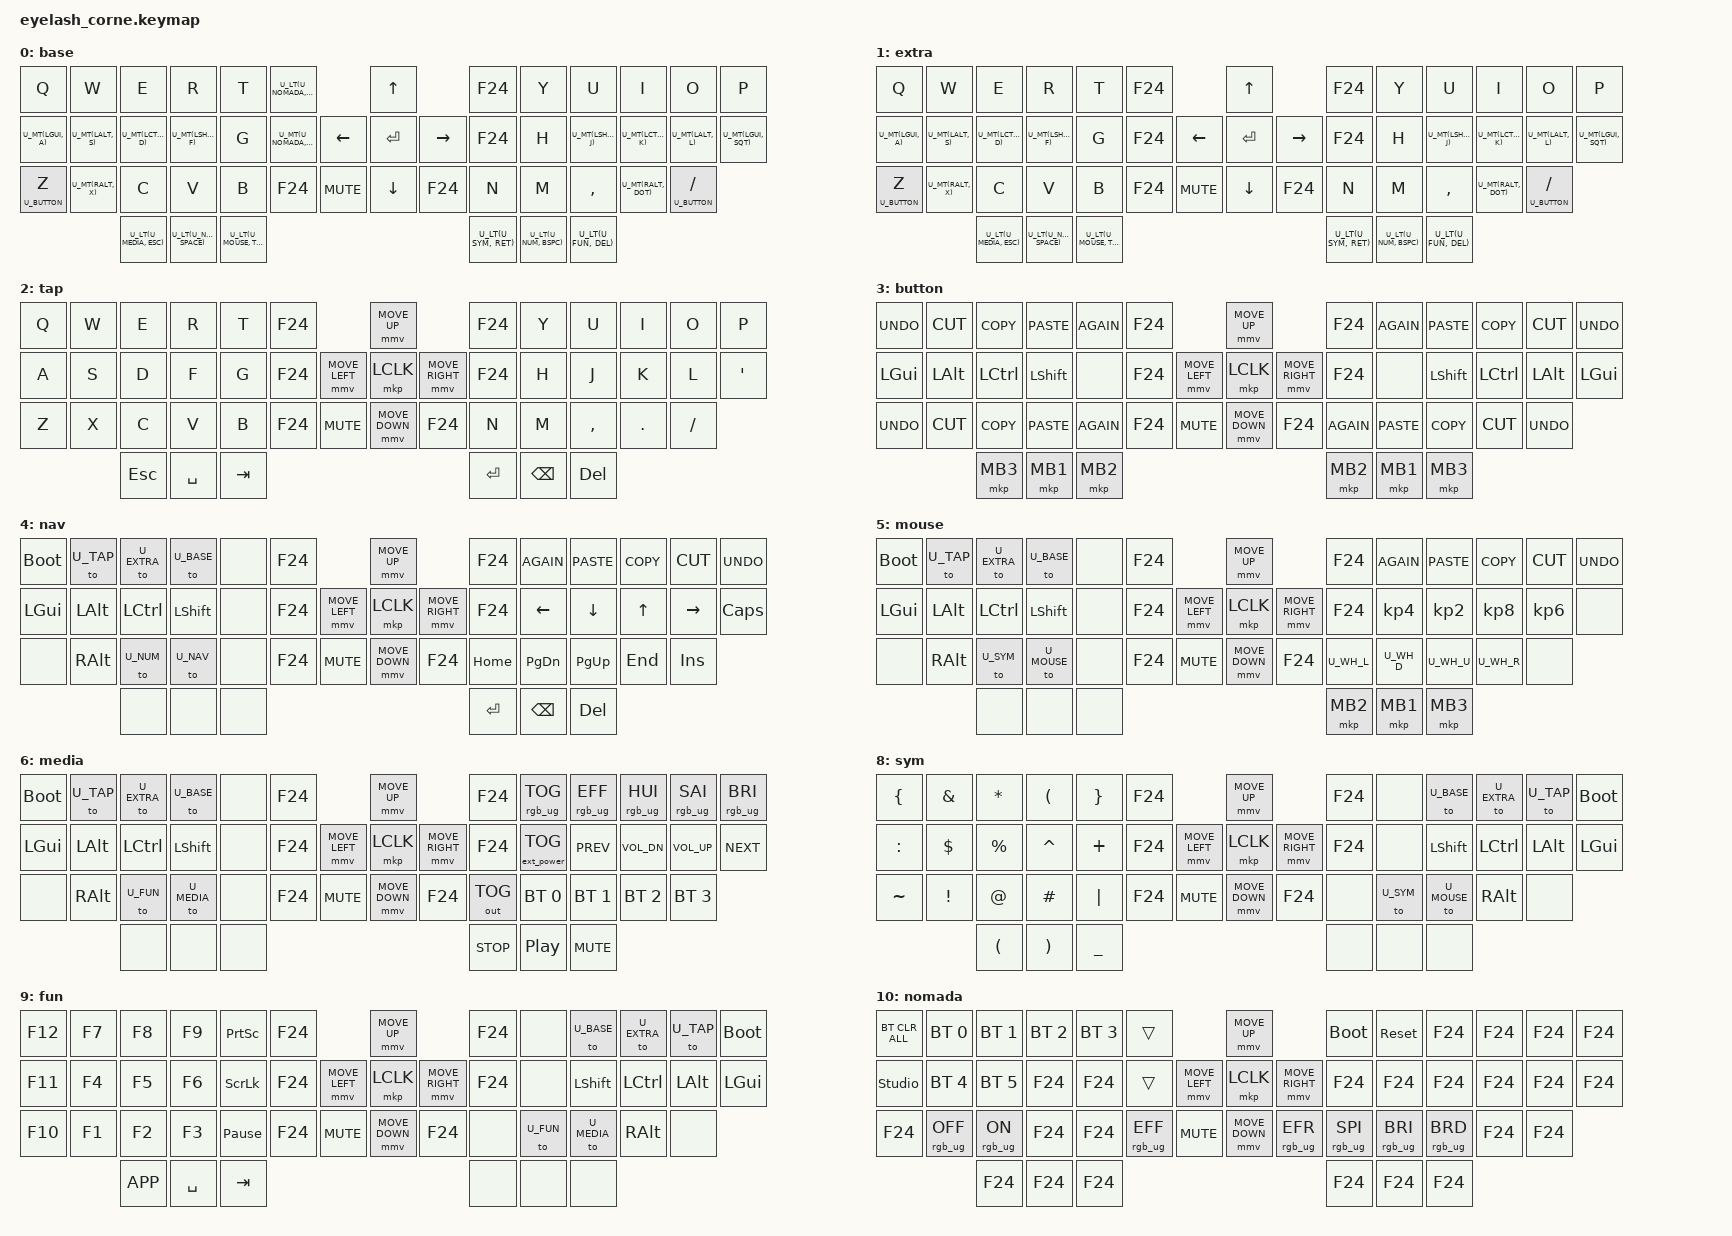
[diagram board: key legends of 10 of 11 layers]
#include <behaviors.dtsi>
#include <dt-bindings/zmk/bt.h>
#include <dt-bindings/zmk/keys.h>
#include <dt-bindings/zmk/mouse.h>
#include <dt-bindings/zmk/outputs.h>
#include <dt-bindings/zmk/rgb.h>
#include <dt-bindings/zmk/ext_power.h>

#include <input/processors.dtsi>

/*

   &mmv_input_listener {
       input-processors = <&zip_xy_scaler 2 1>;
   };

   &msc_input_listener {
       input-processors = <&zip_xy_scaler 2 1>;
   };

 */

#define ZMK_MOUSE_DEFAULT_MOVE_VAL 1200  // 600
#define ZMK_MOUSE_DEFAULT_SCRL_VAL 20    // 10


#define U_RDO &kp K_AGAIN
#define U_PST &kp K_PASTE
#define U_CPY &kp K_COPY
#define U_CUT &kp K_CUT
#define U_UND &kp K_UNDO


#define U_NP &none // key is not present
#define U_NA &none // present but not available for use
#define U_NU &none // available but not used


#define U_MT(MOD, TAP) &u_mt MOD TAP
#define U_LT(LAYER, TAP) &u_lt LAYER TAP


#define U_BASE   0
#define U_EXTRA  1
#define U_TAP    2
#define U_BUTTON 3
#define U_NAV    4
#define U_MOUSE  5
#define U_MEDIA  6
#define U_NUM    7
#define U_SYM    8
#define U_FUN    9
#define U_NOMADA 10

#define U_TAPPING_TERM 200
 
#define U_MS_D &kp KP_N2
#define U_MS_L &kp KP_N4
#define U_MS_R &kp KP_N6
#define U_MS_U &kp KP_N8
#define U_WH_D U_NU
#define U_WH_L U_NU
#define U_WH_R U_NU
#define U_WH_U U_NU


#define U_RGB_TOG &rgb_ug RGB_TOG
#define U_RGB_EFF &rgb_ug RGB_EFF
#define U_RGB_HUI &rgb_ug RGB_HUI
#define U_RGB_SAI &rgb_ug RGB_SAI
#define U_RGB_BRI &rgb_ug RGB_BRI
#define U_EP_TOG &ext_power EP_TOG

#define U_BTN1 &mkp MB1
#define U_BTN2 &mkp MB2
#define U_BTN3 &mkp MB3

// #define MIRYOKU_DOUBLE_TAP_GUARD(NAME, BINDING) \
// / { \
//   behaviors { \
//     NAME: NAME { \
//       compatible = "zmk,behavior-tap-dance"; \
//       #binding-cells = <0>; \
//       tapping-term-ms = <U_TAPPING_TERM>; \
//       bindings = <&none>, <BINDING>; \
//     }; \
//   }; \
// };

// #define MIRYOKU_X(LAYER, STRING) \
// MIRYOKU_DOUBLE_TAP_GUARD(u_to_U_##LAYER, &to U_##LAYER)
// MIRYOKU_LAYER_LIST
// #undef MIRYOKU_X


// #define MIRYOKU_SHIFT_FUNCTION(NAME, BINDING, SHIFT_BINDING) \
// / { \
//   behaviors { \
//     NAME: NAME { \
//       compatible = "zmk,behavior-mod-morph"; \
//       #binding-cells = <0>; \
//       bindings = <BINDING>, <SHIFT_BINDING>; \
//       mods = <(MOD_LSFT|MOD_RSFT)>; \
//     }; \
//   }; \
// };

// #define MIRYOKU_SHIFT_MACRO(NAME, BINDING, SHIFT_BINDING) \
// U_MACRO(u_macro_ ## NAME, wait-ms = <0>; bindings = <SHIFT_BINDING>;) \
// MIRYOKU_SHIFT_FUNCTION(NAME, BINDING, &u_macro_ ## NAME)

// MIRYOKU_SHIFT_MACRO(u_bt_sel_0, &bt BT_SEL 0, &bt BT_SEL 0 &bt BT_CLR)
// MIRYOKU_SHIFT_MACRO(u_bt_sel_1, &bt BT_SEL 1, &bt BT_SEL 1 &bt BT_CLR)
// MIRYOKU_SHIFT_MACRO(u_bt_sel_2, &bt BT_SEL 2, &bt BT_SEL 2 &bt BT_CLR)
// MIRYOKU_SHIFT_MACRO(u_bt_sel_3, &bt BT_SEL 3, &bt BT_SEL 3 &bt BT_CLR)
// MIRYOKU_SHIFT_MACRO(u_bt_sel_4, &bt BT_SEL 4, &bt BT_SEL 4 &bt BT_CLR)
// MIRYOKU_SHIFT_FUNCTION(u_caps_word, &caps_word, &kp CAPS)

// MIRYOKU_SHIFT_FUNCTION(u_out_tog, &out OUT_TOG, &out OUT_USB)

/ {
    behaviors {
        td0: td0 {
            compatible = "zmk,behavior-tap-dance";
            display-name = "Shift/Caps Lock Tap Dance";
            #binding-cells = <0>;
            bindings = <&kp LEFT_SHIFT>, <&kp CAPS>;
        };

        u_mt: u_mt {
            compatible = "zmk,behavior-hold-tap";
            #binding-cells = <2>;
            tapping-term-ms = <U_TAPPING_TERM>;
            flavor = "tap-preferred";
            bindings = <&kp>, <&kp>;
        };

        u_lt: u_lt {
            compatible = "zmk,behavior-hold-tap";
            #binding-cells = <2>;
            tapping-term-ms = <U_TAPPING_TERM>;
            flavor = "tap-preferred";
            bindings = <&mo>, <&kp>;
        };

        gresc: grave_escape {
            compatible = "zmk,behavior-mod-morph";
            #binding-cells = <0>;
            bindings = <&kp ESC>, <&kp GRAVE>;
            mods = <(MOD_LGUI|MOD_LSFT|MOD_RGUI|MOD_RSFT)>;
        };

    };

    rgb_encoder: rgb_encoder {
        compatible = "zmk,behavior-sensor-rotate";
        #sensor-binding-cells = <0>;
        bindings = <&rgb_ug RGB_BRI>, <&rgb_ug RGB_BRD>;
    };

    scroll_encoder: scroll_encoder {
        compatible = "zmk,behavior-sensor-rotate";
        #sensor-binding-cells = <0>;
        bindings = <&msc SCRL_DOWN>, <&msc SCRL_UP>;
        tap-ms = <30>;
    };

    keymap {
        compatible = "zmk,keymap";

    layer_base {
            display-name = "base";
            bindings = <
&kp Q           &kp W          &kp E               &kp R               &kp T  U_LT(U_NOMADA, A)                                 &kp UP                &kp F24           &kp Y              &kp U            &kp I           &kp O            &kp P
U_MT(LGUI, A)   U_MT(LALT, S)  U_MT(LCTRL, D)      U_MT(LSHFT, F)      &kp G  U_MT(U_NOMADA, A)                     &kp LEFT  &kp ENTER  &kp RIGHT  &kp F24           &kp H              U_MT(LSHFT, J)   U_MT(LCTRL, K)  U_MT(LALT, L)    U_MT(LGUI, SQT)
&lt U_BUTTON Z  U_MT(RALT, X)  &kp C               &kp V               &kp B  &kp F24     &kp C_MUTE                &kp DOWN              &kp F24           &kp N              &kp M            &kp COMMA       U_MT(RALT, DOT)  &lt U_BUTTON SLASH
                               U_LT(U_MEDIA, ESC)  U_LT(U_NAV, SPACE)  U_LT(U_MOUSE, TAB)                                                  U_LT(U_SYM, RET)  U_LT(U_NUM, BSPC)  U_LT(U_FUN, DEL)
            >;
            sensor-bindings = <&scroll_encoder>;
        };

        layer_extra {
            display-name = "extra";
            bindings = <
&kp Q           &kp W          &kp E               &kp R               &kp T  &kp F24                               &kp UP                &kp F24           &kp Y              &kp U            &kp I           &kp O            &kp P
U_MT(LGUI, A)   U_MT(LALT, S)  U_MT(LCTRL, D)      U_MT(LSHFT, F)      &kp G  &kp F24                     &kp LEFT  &kp ENTER  &kp RIGHT  &kp F24           &kp H              U_MT(LSHFT, J)   U_MT(LCTRL, K)  U_MT(LALT, L)    U_MT(LGUI, SQT)
&lt U_BUTTON Z  U_MT(RALT, X)  &kp C               &kp V               &kp B  &kp F24     &kp C_MUTE                &kp DOWN              &kp F24           &kp N              &kp M            &kp COMMA       U_MT(RALT, DOT)  &lt U_BUTTON SLASH
                               U_LT(U_MEDIA, ESC)  U_LT(U_NAV, SPACE)  U_LT(U_MOUSE, TAB)                                                  U_LT(U_SYM, RET)  U_LT(U_NUM, BSPC)  U_LT(U_FUN, DEL)
            >;
            sensor-bindings = <&scroll_encoder>;
        };

        layer_tap {
            display-name = "tap";
            bindings = <
&kp Q           &kp W  &kp E    &kp R      &kp T    &kp F24                              &mmv MOVE_UP                     &kp F24  &kp Y     &kp U    &kp I      &kp O    &kp P
&kp A           &kp S  &kp D    &kp F      &kp G    &kp F24              &mmv MOVE_LEFT  &mkp LCLK       &mmv MOVE_RIGHT  &kp F24  &kp H     &kp J    &kp K      &kp L    &kp SQT
&kp Z           &kp X  &kp C    &kp V      &kp B    &kp F24  &kp C_MUTE                  &mmv MOVE_DOWN                   &kp F24  &kp N     &kp M    &kp COMMA  &kp DOT  &kp SLASH
                       &kp ESC  &kp SPACE  &kp TAB                                                                        &kp RET  &kp BSPC  &kp DEL
            >;
            sensor-bindings = <&scroll_encoder>;
        };

        layer_button {
            display-name = "button";
            bindings = <
U_UND           U_CUT     U_CPY      U_PST      U_RDO   &kp F24                              &mmv MOVE_UP                     &kp F24  U_RDO   U_PST      U_CPY      U_CUT    U_UND
&kp LGUI        &kp LALT  &kp LCTRL  &kp LSHFT  U_NU    &kp F24             &mmv MOVE_LEFT  &mkp LCLK       &mmv MOVE_RIGHT  &kp F24  U_NU   &kp LSHFT  &kp LCTRL  &kp LALT  &kp LGUI
U_UND           U_CUT     U_CPY      U_PST      U_RDO   &kp F24  &kp C_MUTE                  &mmv MOVE_DOWN                   &kp F24  U_RDO   U_PST      U_CPY      U_CUT    U_UND
                               U_BTN3     U_BTN1  U_BTN2                                                                U_BTN2   U_BTN1  U_BTN3
            >;
            sensor-bindings = <&scroll_encoder>;
        };

        layer_nav {
            display-name = "nav";
            bindings = <
&bootloader          &to U_TAP  &to U_EXTRA  &to U_BASE  U_NA       &kp F24                               &mmv MOVE_UP                     &kp F24      U_RDO      U_PST        U_CPY       U_CUT            U_UND
&kp LGUI        &kp LALT     &kp LCTRL      &kp LSHFT     U_NA       &kp F24               &mmv MOVE_LEFT  &mkp LCLK       &mmv MOVE_RIGHT  &kp F24      &kp LEFT   &kp DOWN     &kp UP      &kp RIGHT        &kp CAPS
U_NA            &kp RALT     &to U_NUM    &to U_NAV   U_NA       &kp F24   &kp C_MUTE                  &mmv MOVE_DOWN                   &kp F24      &kp HOME   &kp PG_DN    &kp PG_UP   &kp END          &kp INS
                                U_NA        U_NA        U_NA                                                                     &kp RET      &kp BSPC   &kp DEL
            >;
            sensor-bindings = <&scroll_encoder>;
        };

        layer_mouse {
            display-name = "mouse";
            bindings = <
&bootloader           &to U_TAP  &to U_EXTRA  &to U_BASE   U_NA  &kp F24                              &mmv MOVE_UP                     &kp F24  U_RDO    U_PST   U_CPY   U_CUT   U_UND
&kp LGUI         &kp LALT     &kp LCTRL      &kp LSHFT      U_NA  &kp F24              &mmv MOVE_LEFT  &mkp LCLK       &mmv MOVE_RIGHT  &kp F24  U_MS_L   U_MS_D  U_MS_U  U_MS_R  U_NU
U_NA             &kp RALT     &to U_SYM    &to U_MOUSE  U_NA  &kp F24  &kp C_MUTE                  &mmv MOVE_DOWN                   &kp F24  U_WH_L   U_WH_D  U_WH_U  U_WH_R  U_NU
                                      U_NA           U_NA  U_NA                                                                  U_BTN2   U_BTN1   U_BTN3
            >;
            sensor-bindings = <&scroll_encoder>;
        };

        layer_media {
            display-name = "media";
            bindings = <
&bootloader    &to U_TAP  &to U_EXTRA  &to U_BASE   U_NA  &kp F24                              &mmv MOVE_UP                     &kp F24     U_RGB_TOG   U_RGB_EFF    U_RGB_HUI     U_RGB_SAI     U_RGB_BRI
&kp LGUI  &kp LALT     &kp LCTRL      &kp LSHFT      U_NA  &kp F24              &mmv MOVE_LEFT  &mkp LCLK       &mmv MOVE_RIGHT  &kp F24     U_EP_TOG    &kp C_PREV   &kp C_VOL_DN  &kp C_VOL_UP  &kp C_NEXT
U_NA      &kp RALT     &to U_FUN    &to U_MEDIA  U_NA  &kp F24  &kp C_MUTE                  &mmv MOVE_DOWN                   &kp F24     &out OUT_TOG  &bt BT_SEL 0  &bt BT_SEL 1   &bt BT_SEL 2  &bt BT_SEL 3
                                      U_NA           U_NA  U_NA                                                                  &kp C_STOP  &kp C_PP    &kp C_MUTE
            >;
            sensor-bindings = <&scroll_encoder>;
        };

        layer_num {
            display-name = "num";
            bindings = <
&kp LBKT        &kp N7      &kp N8      &kp N9       &kp RBKT  &kp F24                                 &mmv MOVE_UP                     &kp F24      U_NA       &to U_BASE  &to U_EXTRA  &to U_TAP      &bootloader
&kp SEMI        &kp N4      &kp N5      &kp N6       &kp EQUAL &kp F24                 &mmv MOVE_LEFT  &mkp LCLK       &mmv MOVE_RIGHT  &kp F24      U_NA       &kp LSHFT     &kp LCTRL      &kp LALT         &kp LGUI
&kp GRAVE       &kp N1      &kp N2      &kp N3       &kp BSLH  &kp F24   &kp C_MUTE                  &mmv MOVE_DOWN                   &kp F24      U_NA       &to U_NUM   &to U_NAV    &kp RALT         U_NA                                  &kp DOT     &kp N0      &kp MINUS                                                                U_NA         U_NA       U_NA              
                                &trans      &trans      &trans                                                                   &trans       &trans     &trans
            >;
            sensor-bindings = <&scroll_encoder>;
        };

        layer_sym {
            display-name = "sym";
            bindings = <
&kp LBRC        &kp AMPS    &kp ASTRK   &kp LPAR     &kp RBRC   &kp F24                                 &mmv MOVE_UP                     &kp F24      U_NA       &to U_BASE  &to U_EXTRA  &to U_TAP      &bootloader
&kp COLON       &kp DLLR    &kp PRCNT   &kp CARET    &kp PLUS   &kp F24                 &mmv MOVE_LEFT  &mkp LCLK       &mmv MOVE_RIGHT  &kp F24      U_NA       &kp LSHFT     &kp LCTRL      &kp LALT         &kp LGUI
&kp TILDE       &kp EXCL    &kp AT      &kp HASH     &kp PIPE   &kp F24   &kp C_MUTE                    &mmv MOVE_DOWN                   &kp F24      U_NA       &to U_SYM   &to U_MOUSE  &kp RALT         U_NA  
                                &kp LPAR    &kp RPAR    &kp UNDER                                                                U_NA         U_NA       U_NA              
            >;
            sensor-bindings = <&scroll_encoder>;
        };

        layer_fun {
            display-name = "fun";
            bindings = <
&kp F12          &kp F7      &kp F8      &kp F9       &kp PSCRN        &kp F24                                 &mmv MOVE_UP                     &kp F24      U_NA       &to U_BASE  &to U_EXTRA  &to U_TAP      &bootloader
&kp F11          &kp F4      &kp F5      &kp F6       &kp SLCK         &kp F24                 &mmv MOVE_LEFT  &mkp LCLK       &mmv MOVE_RIGHT  &kp F24      U_NA       &kp LSHFT     &kp LCTRL      &kp LALT         &kp LGUI
&kp F10          &kp F1      &kp F2      &kp F3       &kp PAUSE_BREAK  &kp F24   &kp C_MUTE                    &mmv MOVE_DOWN                   &kp F24      U_NA       &to U_FUN   &to U_MEDIA  &kp RALT         U_NA  
                                &kp K_APP   &kp SPACE   &kp TAB                                                                  U_NA         U_NA       U_NA              
            >;
            sensor-bindings = <&scroll_encoder>;
        };

        layer_nomada {
            display-name = "nomada";
            bindings = <
&bt BT_CLR_ALL  &bt BT_SEL 0     &bt BT_SEL 1    &bt BT_SEL 2  &bt BT_SEL 3   &trans                                       &mmv MOVE_UP                     &bootloader      &sys_reset       &kp F24          &kp F24          &kp F24  &kp F24
&studio_unlock  &bt BT_SEL 4     &bt BT_SEL 5    &kp F24       &kp F24        &trans                       &mmv MOVE_LEFT  &mkp LCLK       &mmv MOVE_RIGHT  &kp F24          &kp F24          &kp F24          &kp F24          &kp F24  &kp F24
&kp F24         &rgb_ug RGB_OFF  &rgb_ug RGB_ON  &kp F24       &kp F24        &rgb_ug RGB_EFF  &kp C_MUTE                  &mmv MOVE_DOWN                   &rgb_ug RGB_EFR  &rgb_ug RGB_SPI  &rgb_ug RGB_BRI  &rgb_ug RGB_BRD  &kp F24  &kp F24
                                                 &kp F24       &kp F24        &kp F24                                                                       &kp F24          &kp F24          &kp F24
            >;
            sensor-bindings = <&scroll_encoder>;
        };

    };
};
